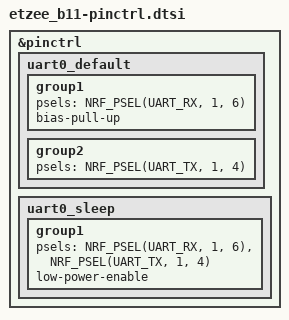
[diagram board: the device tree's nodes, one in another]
&pinctrl {
    uart0_default: uart0_default {
        group1 {
            psels = <NRF_PSEL(UART_RX, 1, 6)>;
            bias-pull-up;
        };
        group2 {
            psels = <NRF_PSEL(UART_TX, 1, 4)>;
        };
    };

    uart0_sleep: uart0_sleep {
        group1 {
            psels = <NRF_PSEL(UART_RX, 1, 6)>,
                    <NRF_PSEL(UART_TX, 1, 4)>;
            low-power-enable;
        };
    };
};
